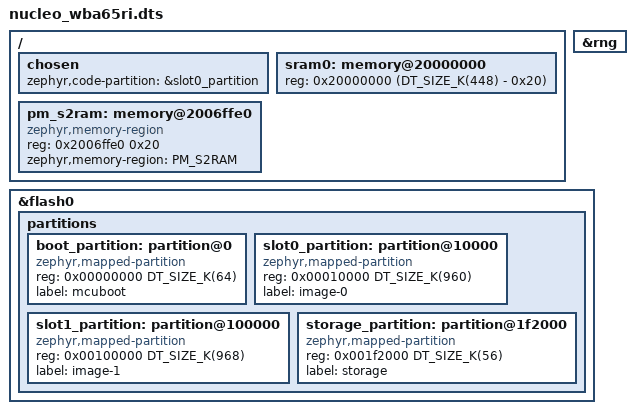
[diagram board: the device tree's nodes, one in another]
/*
 * Copyright (c)  2025 STMicroelectronics
 *
 * SPDX-License-Identifier: Apache-2.0
 */

/dts-v1/;
#include "nucleo_wba65ri-common.dtsi"
#include <mem.h>

/ {
	chosen {
		zephyr,code-partition = &slot0_partition;
	};

	/* Exclude the final 0x20 bytes reserved for the PM_S2RAM marker */
	sram0: memory@20000000 {
		reg = <0x20000000 (DT_SIZE_K(448) - 0x20)>;
	};

	/* Reserve a fixed retained RAM window for the S2RAM CPU context so both
	 * the application and MCUboot place `_cpu_context` at the same physical
	 * address.
	 */
	pm_s2ram: memory@2006ffe0 {
		compatible = "zephyr,memory-region", "mmio-sram";
		reg = <0x2006ffe0 0x20>;
		zephyr,memory-region = "PM_S2RAM";
	};
};

&rng {
	status = "okay";
};

&flash0 {
	partitions {
		ranges;
		#address-cells = <1>;
		#size-cells = <1>;

		boot_partition: partition@0 {
			compatible = "zephyr,mapped-partition";
			reg = <0x00000000 DT_SIZE_K(64)>;
			label = "mcuboot";
		};

		slot0_partition: partition@10000 {
			compatible = "zephyr,mapped-partition";
			reg = <0x00010000 DT_SIZE_K(960)>;
			label = "image-0";
		};

		slot1_partition: partition@100000 {
			compatible = "zephyr,mapped-partition";
			reg = <0x00100000 DT_SIZE_K(968)>;
			label = "image-1";
		};

		storage_partition: partition@1f2000 {
			compatible = "zephyr,mapped-partition";
			reg = <0x001f2000 DT_SIZE_K(56)>;
			label = "storage";
		};
	};
};
